VERSION ""

NS_ :

BS_:

BU_: ECU_A ECU_B

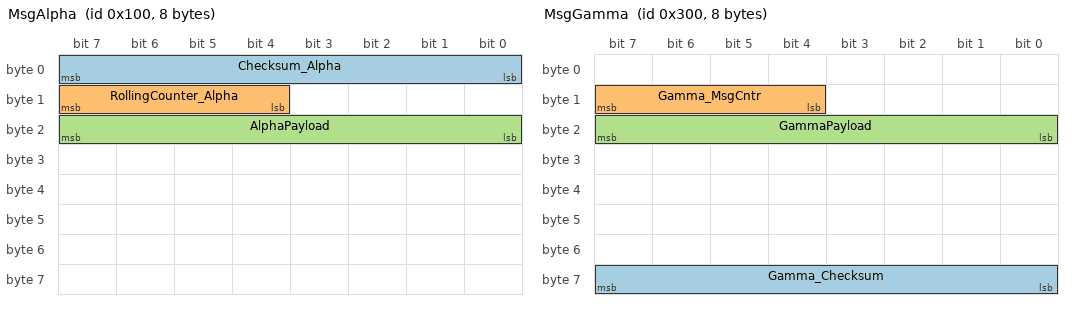
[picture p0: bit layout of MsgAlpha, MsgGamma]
BO_ 256 MsgAlpha: 8 ECU_A
 SG_ Checksum_Alpha : 7|8@0+ (1,0) [0|255] "" ECU_B
 SG_ RollingCounter_Alpha : 15|4@0+ (1,0) [0|15] "" ECU_B
 SG_ AlphaPayload : 23|8@0+ (1,0) [0|255] "" ECU_B

BO_ 512 MsgBeta: 64 ECU_A
 SG_ Beta_CRC : 7|16@0+ (1,0) [0|65535] "" ECU_B
 SG_ Beta_Counter : 23|8@0+ (1,0) [0|255] "" ECU_B
 SG_ BetaPayload : 31|8@0+ (1,0) [0|255] "" ECU_B

BO_ 768 MsgGamma: 8 ECU_A
 SG_ Gamma_Checksum : 63|8@0+ (1,0) [0|255] "" ECU_B
 SG_ Gamma_MsgCntr : 15|4@0+ (1,0) [0|15] "" ECU_B
 SG_ GammaPayload : 23|8@0+ (1,0) [0|255] "" ECU_B

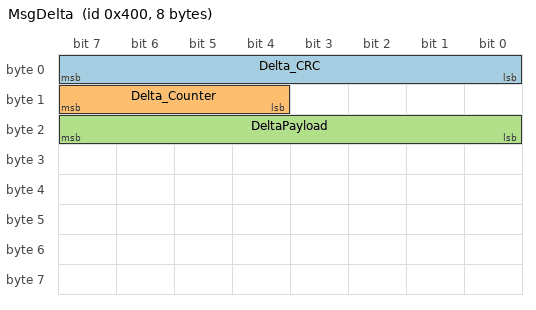
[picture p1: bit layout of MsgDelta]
BO_ 1024 MsgDelta: 8 ECU_A
 SG_ Delta_CRC : 7|8@0+ (1,0) [0|255] "" ECU_B
 SG_ Delta_Counter : 15|4@0+ (1,0) [0|15] "" ECU_B
 SG_ DeltaPayload : 23|8@0+ (1,0) [0|255] "" ECU_B

CM_ SG_ 256 Checksum_Alpha "E2E Profile 1A CRC";
CM_ SG_ 512 Beta_CRC "E2E Profile 5 CRC";
CM_ SG_ 768 Gamma_Checksum "Checksum = ((Byte0+Byte1+Byte2+Byte3+Byte4+Byte5+Byte6) AND 0xFF) XOR 0xFF";
CM_ SG_ 1024 Delta_CRC "CRC (SAE J1850 CRC-8)";
